# MKL34Z4 register map
Vendor: Freescale Semiconductor, Inc.; File version: 1.6
CPU: CM0PLUS r0p0, little endian, no MPU, no FPU, 0x2 interrupt priority bits, 0x0 interrupts
Registers are 32-bit, read-write, reset 0x0 unless marked. A register's access mark holds for its fields unless they carry their own. Offsets are from the block's base; [hi:lo] are bit positions; {n}, {i} and the like mark numbered series; 'fields as' and 'values as' point back to an identical list.

## PORTA — Pin Control and Interrupts
Base 0x40049000; register names take the prefix PORTA_
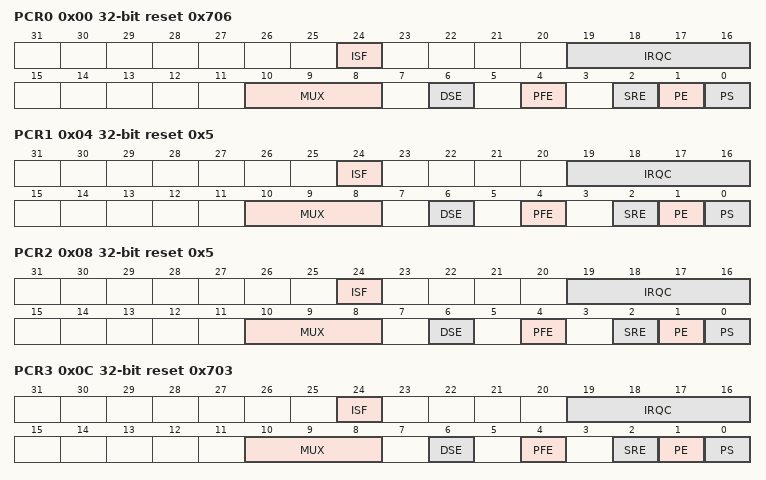
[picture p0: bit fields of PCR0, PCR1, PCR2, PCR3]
0x00 PCR0 reset 0x706 — Pin Control Register n
  [24] ISF — Interrupt Status Flag
    0=Configured interrupt is not detected; 1=Configured interrupt is detected. If the pin is configured to generate a DMA request, then the corresponding flag will be cleared automatically at the completion of the requested DMA transfer. Otherwise, the flag remains set until a logic one is written to the flag. If the pin is configured for a level sensitive interrupt and the pin remains asserted, then the flag is set again immediately after it is cleared.
  [19:16] IRQC — Interrupt Configuration
    0=Interrupt/DMA request disabled; 1=DMA request on rising edge; 2=DMA request on falling edge; 3=DMA request on either edge; 8=Interrupt when logic zero; 9=Interrupt on rising edge; 10=Interrupt on falling edge; 11=Interrupt on either edge; 12=Interrupt when logic one
  [10:8] MUX — Pin Mux Control
    0=Pin disabled (analog); 1=Alternative 1 (GPIO); {v}=Alternative {v} (chip-specific) (v=2..7)
  [6] DSE ro — Drive Strength Enable
    0=Low drive strength is configured on the corresponding pin, if pin is configured as a digital output; 1=High drive strength is configured on the corresponding pin, if pin is configured as a digital output
  [4] PFE ro — Passive Filter Enable
    0=Passive input filter is disabled on the corresponding pin; 1=Passive input filter is enabled on the corresponding pin, if the pin is configured as a digital input. Refer to the device data sheet for filter characteristics.
  [2] SRE — Slew Rate Enable
    0=Fast slew rate is configured on the corresponding pin, if the pin is configured as a digital output; 1=Slow slew rate is configured on the corresponding pin, if the pin is configured as a digital output
  [1] PE — Pull Enable
    0=Internal pullup or pulldown resistor is not enabled on the corresponding pin; 1=Internal pullup or pulldown resistor is enabled on the corresponding pin, if the pin is configured as a digital input
  [0] PS — Pull Select
    0=Internal pulldown resistor is enabled on the corresponding pin, if the corresponding Port Pull Enable field is set; 1=Internal pullup resistor is enabled on the corresponding pin, if the corresponding Port Pull Enable field is set
0x04 PCR1 reset 0x5 — Pin Control Register n
  fields as PCR0
0x08 PCR2 reset 0x5 — Pin Control Register n
  fields as PCR0
0x0C PCR3 reset 0x703 — Pin Control Register n
  fields as PCR0
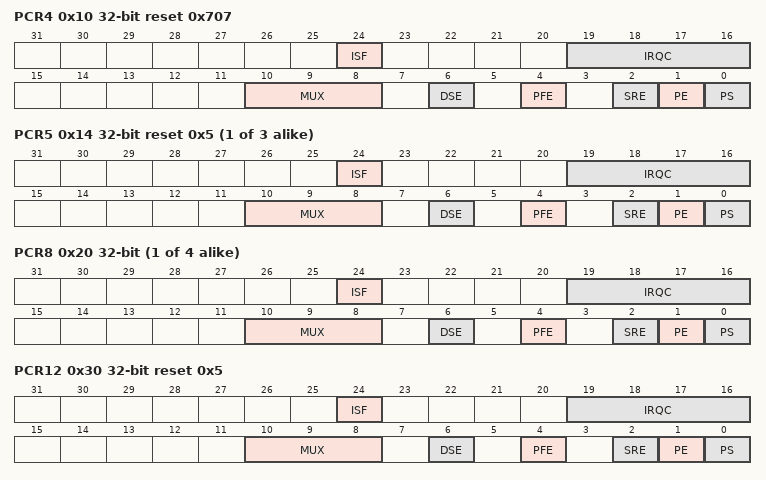
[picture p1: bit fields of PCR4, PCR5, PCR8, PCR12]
0x10 PCR4 reset 0x707 — Pin Control Register n
  [24] ISF — Interrupt Status Flag
    values as PCR0.ISF
  [19:16] IRQC — Interrupt Configuration
    values as PCR0.IRQC
  [10:8] MUX — Pin Mux Control
    values as PCR0.MUX
  [6] DSE ro — Drive Strength Enable
    values as PCR0.DSE
  [4] PFE — Passive Filter Enable
    values as PCR0.PFE
  [2] SRE — Slew Rate Enable
    values as PCR0.SRE
  [1] PE — Pull Enable
    values as PCR0.PE
  [0] PS — Pull Select
    values as PCR0.PS
{0x0+4i} PCR{i} reset 0x5 (i=5..7) — Pin Control Register n
  fields as PCR0
{0x0+4i} PCR{i} (i=8..11) — Pin Control Register n
  [24] ISF — Interrupt Status Flag
    values as PCR0.ISF
  [19:16] IRQC — Interrupt Configuration
    values as PCR0.IRQC
  [10:8] MUX — Pin Mux Control
    values as PCR0.MUX
  [6] DSE ro — Drive Strength Enable
    values as PCR0.DSE
  [4] PFE ro — Passive Filter Enable
    values as PCR0.PFE
  [2] SRE ro — Slew Rate Enable
    values as PCR0.SRE
  [1] PE ro — Pull Enable
    values as PCR0.PE
  [0] PS ro — Pull Select
    values as PCR0.PS
0x30 PCR12 reset 0x5 — Pin Control Register n
  fields as PCR0
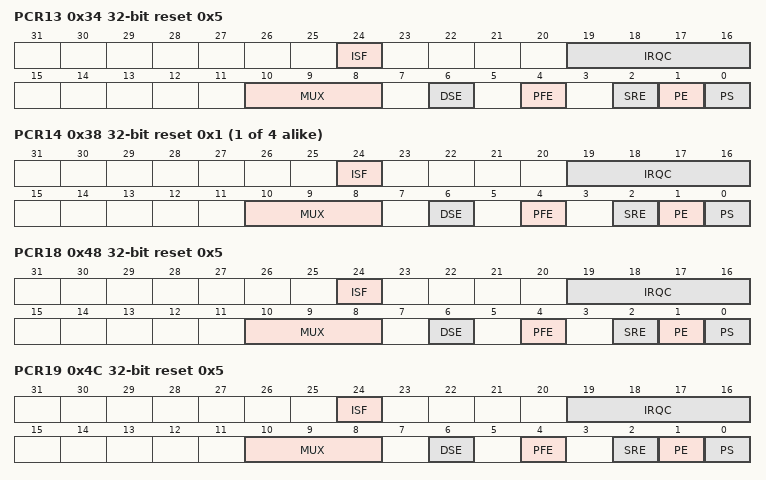
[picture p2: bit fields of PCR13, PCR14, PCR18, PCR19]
0x34 PCR13 reset 0x5 — Pin Control Register n
  fields as PCR0
{0x0+4i} PCR{i} reset 0x1 (i=14..17) — Pin Control Register n
  fields as PCR0
0x48 PCR18 reset 0x5 — Pin Control Register n
  fields as PCR0
0x4C PCR19 reset 0x5 — Pin Control Register n
  fields as PCR0
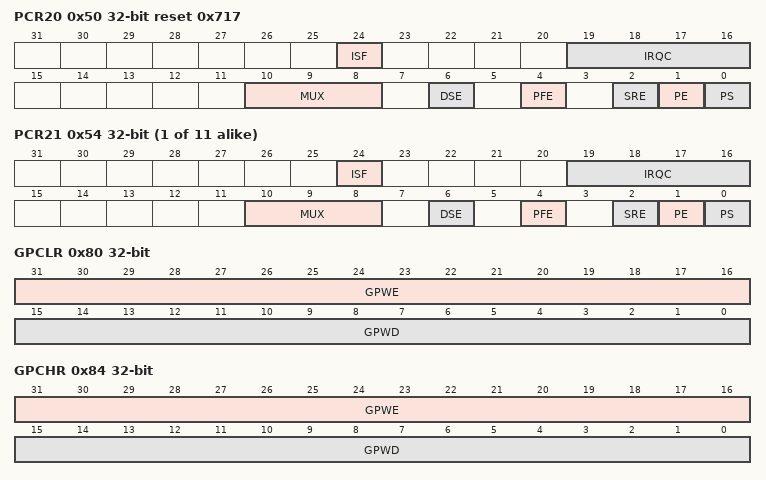
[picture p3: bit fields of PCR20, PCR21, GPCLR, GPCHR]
0x50 PCR20 reset 0x717 — Pin Control Register n
  fields as PCR4
{0x0+4i} PCR{i} (i=21..31) — Pin Control Register n
  fields as PCR8
0x80 GPCLR wo — Global Pin Control Low Register
  [31:16] GPWE — Global Pin Write Enable
    0=Corresponding Pin Control Register is not updated with the value in GPWD; 1=Corresponding Pin Control Register is updated with the value in GPWD
  [15:0] GPWD — Global Pin Write Data
0x84 GPCHR wo — Global Pin Control High Register
  fields as GPCLR
0xA0 ISFR — Interrupt Status Flag Register
  [31:0] ISF — Interrupt Status Flag
    values as PCR0.ISF

## PORTD — Pin Control and Interrupts
Base 0x4004C000; register names take the prefix PORTD_
Registers as PORTA; these are added or differ:
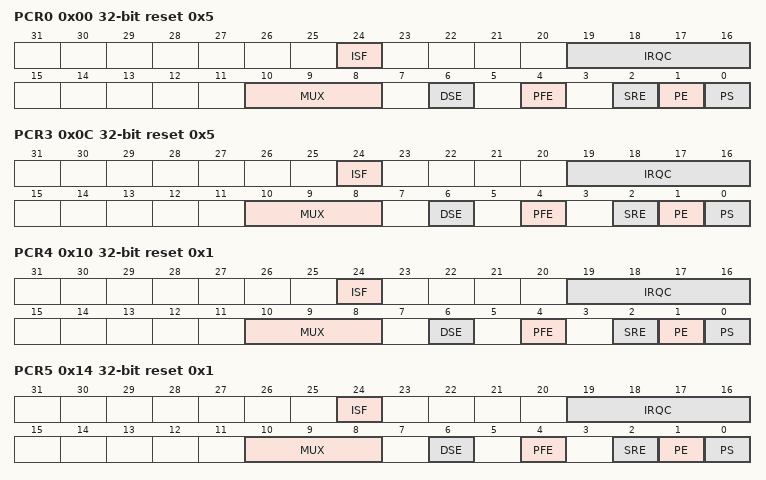
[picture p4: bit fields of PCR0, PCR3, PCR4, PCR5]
0x00 PCR0 reset 0x5 — Pin Control Register n
  fields as PORTA.PCR0
0x0C PCR3 reset 0x5 — Pin Control Register n
  fields as PORTA.PCR0
0x10 PCR4 reset 0x1 — Pin Control Register n
  fields as PORTA.PCR0
0x14 PCR5 reset 0x1 — Pin Control Register n
  fields as PORTA.PCR0
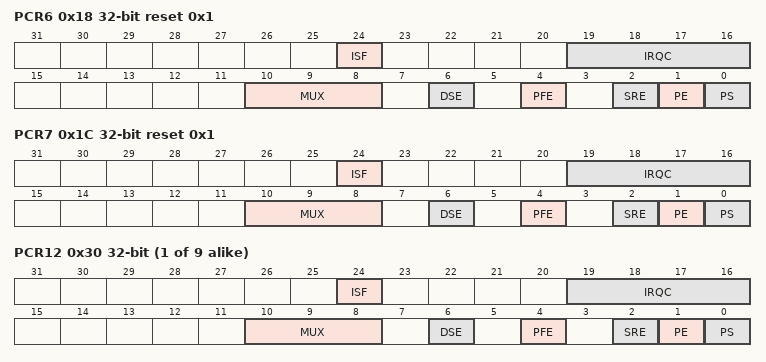
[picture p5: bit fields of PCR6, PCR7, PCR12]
0x18 PCR6 reset 0x1 — Pin Control Register n
  [24] ISF — Interrupt Status Flag
    values as PORTA.PCR0.ISF
  [19:16] IRQC — Interrupt Configuration
    values as PORTA.PCR0.IRQC
  [10:8] MUX — Pin Mux Control
    0=Pin disabled (analog); 1=Alternative 1 (GPIO); {v}=Alternative {v} (chip-specific) (v=2..7)
  [6] DSE — Drive Strength Enable
    values as PORTA.PCR0.DSE
  [4] PFE ro — Passive Filter Enable
    values as PORTA.PCR0.PFE
  [2] SRE — Slew Rate Enable
    values as PORTA.PCR0.SRE
  [1] PE — Pull Enable
    0=Internal pullup or pulldown resistor is not enabled on the corresponding pin; 1=Internal pullup or pulldown resistor is enabled on the corresponding pin, if the pin is configured as a digital input
  [0] PS — Pull Select
    values as PORTA.PCR0.PS
0x1C PCR7 reset 0x1 — Pin Control Register n
  fields as PCR6
{0x0+4i} PCR{i} (i=12..20) — Pin Control Register n
  fields as PORTA.PCR8
